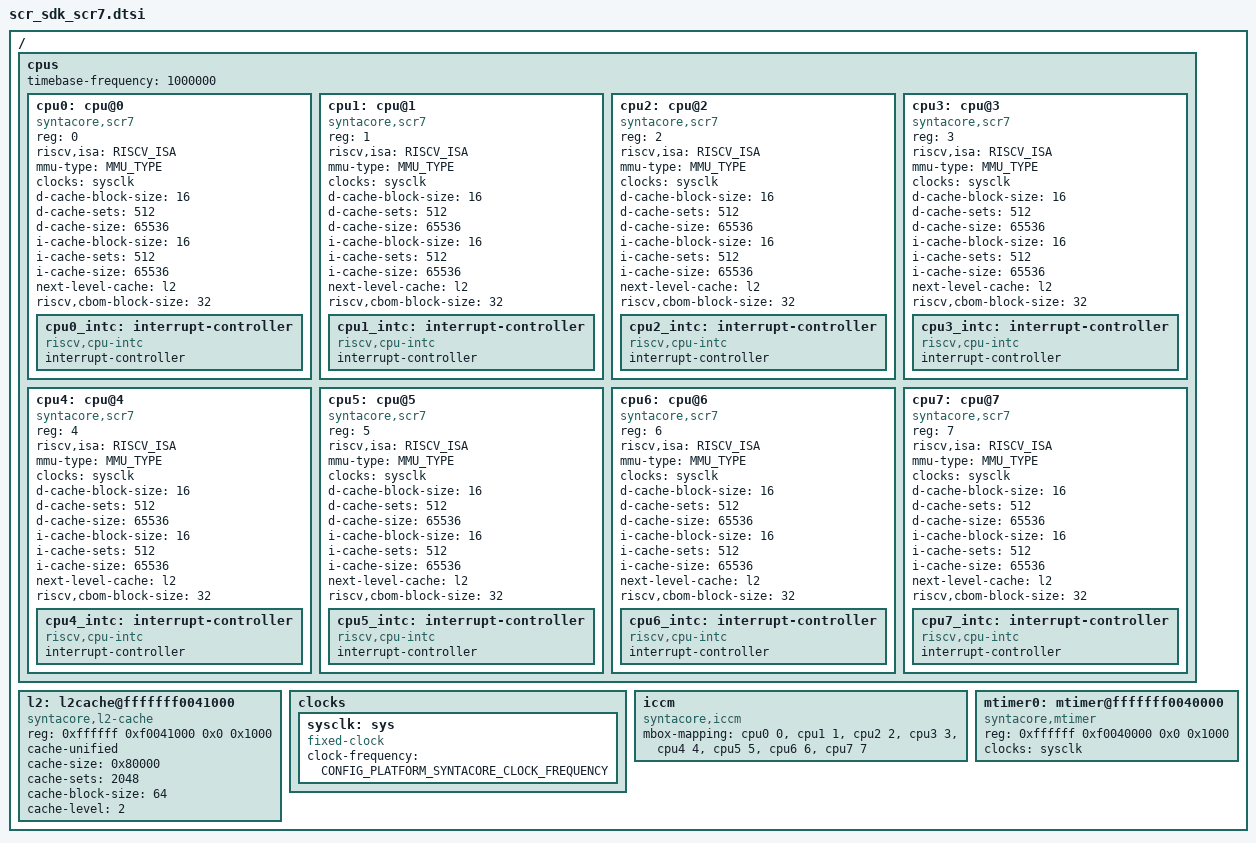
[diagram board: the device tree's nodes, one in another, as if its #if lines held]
/*
 * Copyright (C) 2022, Syntacore Ltd.
 *
 * Redistribution and use in source and binary forms, with or without
 * modification, are permitted provided that the following conditions are met:
 *     1. Redistributions of source code must retain the above copyright notice,
 *        this list of conditions and the following disclaimer.
 *     2. Redistributions in binary form must reproduce the above copyright
 *        notice, this list of conditions and the following disclaimer in the
 *        documentation and/or other materials provided with the distribution.
 *     3. Neither the name of the copyright holder nor the names of its
 *        contributors may be used to endorse or promote products derived from
 *        this software without specific prior written permission.
 *
 * THIS SOFTWARE IS PROVIDED BY THE COPYRIGHT HOLDERS AND CONTRIBUTORS "AS IS" AND
 * ANY EXPRESS OR IMPLIED WARRANTIES, INCLUDING, BUT NOT LIMITED TO, THE IMPLIED
 * WARRANTIES OF MERCHANTABILITY AND FITNESS FOR A PARTICULAR PURPOSE ARE
 * DISCLAIMED. IN NO EVENT SHALL THE COPYRIGHT HOLDER OR CONTRIBUTORS BE LIABLE
 * FOR ANY DIRECT, INDIRECT, INCIDENTAL, SPECIAL, EXEMPLARY, OR CONSEQUENTIAL
 * DAMAGES (INCLUDING, BUT NOT LIMITED TO, PROCUREMENT OF SUBSTITUTE GOODS OR
 * SERVICES; LOSS OF USE, DATA, OR PROFITS; OR BUSINESS INTERRUPTION) HOWEVER
 * CAUSED AND ON ANY THEORY OF LIABILITY, WHETHER IN CONTRACT, STRICT LIABILITY,
 * OR TORT (INCLUDING NEGLIGENCE OR OTHERWISE) ARISING IN ANY WAY OUT OF THE USE
 * OF THIS SOFTWARE, EVEN IF ADVISED OF THE POSSIBILITY OF SUCH DAMAGE.
 */

#define RISCV_ISA	"rv64imafdc_sscofpmf"
#define MMU_TYPE	"riscv,sv39"

/ {
	cpus {
		#address-cells = <1>;
		#size-cells = <0>;
		timebase-frequency = <1000000>;

		cpu0: cpu@0 {
			device_type = "cpu";
			reg = <0>;
			status = "okay";
			compatible = "syntacore,scr7","riscv";
			riscv,isa = RISCV_ISA;
			mmu-type = MMU_TYPE;
			clocks = <&sysclk>;
			d-cache-block-size = <16>;
			d-cache-sets = <512>;
			d-cache-size = <65536>;
			i-cache-block-size = <16>;
			i-cache-sets = <512>;
			i-cache-size = <65536>;
			next-level-cache = <&l2>;
			riscv,cbom-block-size = <32>;

			cpu0_intc: interrupt-controller {
				#address-cells = <0>;
				#interrupt-cells = <1>;
				interrupt-controller;
				compatible = "riscv,cpu-intc";
			};
		};

#if CONFIG_PLATFORM_SYNTACORE_NR_CPUS > 1
		cpu1: cpu@1 {
			device_type = "cpu";
			reg = <1>;
			status = "okay";
			compatible = "syntacore,scr7","riscv";
			riscv,isa = RISCV_ISA;
			mmu-type = MMU_TYPE;
			clocks = <&sysclk>;
			d-cache-block-size = <16>;
			d-cache-sets = <512>;
			d-cache-size = <65536>;
			i-cache-block-size = <16>;
			i-cache-sets = <512>;
			i-cache-size = <65536>;
			next-level-cache = <&l2>;
			riscv,cbom-block-size = <32>;

			cpu1_intc: interrupt-controller {
				#address-cells = <0>;
				#interrupt-cells = <1>;
				interrupt-controller;
				compatible = "riscv,cpu-intc";
			};
		};
#endif

#if CONFIG_PLATFORM_SYNTACORE_NR_CPUS > 2
		cpu2: cpu@2 {
			device_type = "cpu";
			reg = <2>;
			status = "okay";
			compatible = "syntacore,scr7","riscv";
			riscv,isa = RISCV_ISA;
			mmu-type = MMU_TYPE;
			clocks = <&sysclk>;
			d-cache-block-size = <16>;
			d-cache-sets = <512>;
			d-cache-size = <65536>;
			i-cache-block-size = <16>;
			i-cache-sets = <512>;
			i-cache-size = <65536>;
			next-level-cache = <&l2>;
			riscv,cbom-block-size = <32>;

			cpu2_intc: interrupt-controller {
				#address-cells = <0>;
				#interrupt-cells = <1>;
				interrupt-controller;
				compatible = "riscv,cpu-intc";
			};
		};
#endif

#if CONFIG_PLATFORM_SYNTACORE_NR_CPUS > 3
		cpu3: cpu@3 {
			device_type = "cpu";
			reg = <3>;
			status = "okay";
			compatible = "syntacore,scr7","riscv";
			riscv,isa = RISCV_ISA;
			mmu-type = MMU_TYPE;
			clocks = <&sysclk>;
			d-cache-block-size = <16>;
			d-cache-sets = <512>;
			d-cache-size = <65536>;
			i-cache-block-size = <16>;
			i-cache-sets = <512>;
			i-cache-size = <65536>;
			next-level-cache = <&l2>;
			riscv,cbom-block-size = <32>;

			cpu3_intc: interrupt-controller {
				#address-cells = <0>;
				#interrupt-cells = <1>;
				interrupt-controller;
				compatible = "riscv,cpu-intc";
			};
		};
#endif

#if CONFIG_PLATFORM_SYNTACORE_NR_CPUS > 4
		cpu4: cpu@4 {
			device_type = "cpu";
			reg = <4>;
			status = "okay";
			compatible = "syntacore,scr7","riscv";
			riscv,isa = RISCV_ISA;
			mmu-type = MMU_TYPE;
			clocks = <&sysclk>;
			d-cache-block-size = <16>;
			d-cache-sets = <512>;
			d-cache-size = <65536>;
			i-cache-block-size = <16>;
			i-cache-sets = <512>;
			i-cache-size = <65536>;
			next-level-cache = <&l2>;
			riscv,cbom-block-size = <32>;

			cpu4_intc: interrupt-controller {
				#address-cells = <0>;
				#interrupt-cells = <1>;
				interrupt-controller;
				compatible = "riscv,cpu-intc";
			};
		};
#endif

#if CONFIG_PLATFORM_SYNTACORE_NR_CPUS > 5
		cpu5: cpu@5 {
			device_type = "cpu";
			reg = <5>;
			status = "okay";
			compatible = "syntacore,scr7","riscv";
			riscv,isa = RISCV_ISA;
			mmu-type = MMU_TYPE;
			clocks = <&sysclk>;
			d-cache-block-size = <16>;
			d-cache-sets = <512>;
			d-cache-size = <65536>;
			i-cache-block-size = <16>;
			i-cache-sets = <512>;
			i-cache-size = <65536>;
			next-level-cache = <&l2>;
			riscv,cbom-block-size = <32>;

			cpu5_intc: interrupt-controller {
				#address-cells = <0>;
				#interrupt-cells = <1>;
				interrupt-controller;
				compatible = "riscv,cpu-intc";
			};
		};
#endif

#if CONFIG_PLATFORM_SYNTACORE_NR_CPUS > 6
		cpu6: cpu@6 {
			device_type = "cpu";
			reg = <6>;
			status = "okay";
			compatible = "syntacore,scr7","riscv";
			riscv,isa = RISCV_ISA;
			mmu-type = MMU_TYPE;
			clocks = <&sysclk>;
			d-cache-block-size = <16>;
			d-cache-sets = <512>;
			d-cache-size = <65536>;
			i-cache-block-size = <16>;
			i-cache-sets = <512>;
			i-cache-size = <65536>;
			next-level-cache = <&l2>;
			riscv,cbom-block-size = <32>;

			cpu6_intc: interrupt-controller {
				#address-cells = <0>;
				#interrupt-cells = <1>;
				interrupt-controller;
				compatible = "riscv,cpu-intc";
			};
		};
#endif

#if CONFIG_PLATFORM_SYNTACORE_NR_CPUS > 7
		cpu7: cpu@7 {
			device_type = "cpu";
			reg = <7>;
			status = "okay";
			compatible = "syntacore,scr7","riscv";
			riscv,isa = RISCV_ISA;
			mmu-type = MMU_TYPE;
			clocks = <&sysclk>;
			d-cache-block-size = <16>;
			d-cache-sets = <512>;
			d-cache-size = <65536>;
			i-cache-block-size = <16>;
			i-cache-sets = <512>;
			i-cache-size = <65536>;
			next-level-cache = <&l2>;
			riscv,cbom-block-size = <32>;

			cpu7_intc: interrupt-controller {
				#address-cells = <0>;
				#interrupt-cells = <1>;
				interrupt-controller;
				compatible = "riscv,cpu-intc";
			};
		};
#endif
	};

	l2: l2cache@fffffff0041000 {
		compatible = "syntacore,l2-cache", "cache";
		reg = <0xffffff 0xf0041000 0x0 0x1000>;
		cache-unified;
		cache-size = <0x80000>; // 512 KB
		cache-sets = <2048>;
		cache-block-size = <64>;
		cache-level = <2>;
	};

	clocks {
		sysclk: sys {
			compatible = "fixed-clock";
			#clock-cells = <0>;
			clock-frequency = <CONFIG_PLATFORM_SYNTACORE_CLOCK_FREQUENCY>;
		};
	};

	iccm {
		compatible = "syntacore,iccm";
		mbox-mapping = <
			&cpu0 0
#if CONFIG_PLATFORM_SYNTACORE_NR_CPUS > 1
			&cpu1 1
#endif
#if CONFIG_PLATFORM_SYNTACORE_NR_CPUS > 2
			&cpu2 2
#endif
#if CONFIG_PLATFORM_SYNTACORE_NR_CPUS > 3
			&cpu3 3
#endif
#if CONFIG_PLATFORM_SYNTACORE_NR_CPUS > 4
			&cpu4 4
#endif
#if CONFIG_PLATFORM_SYNTACORE_NR_CPUS > 5
			&cpu5 5
#endif
#if CONFIG_PLATFORM_SYNTACORE_NR_CPUS > 6
			&cpu6 6
#endif
#if CONFIG_PLATFORM_SYNTACORE_NR_CPUS > 7
			&cpu7 7
#endif
		>;
	};

	mtimer0: mtimer@fffffff0040000 {
		compatible = "syntacore,mtimer";
		reg = <0xffffff 0xf0040000 0x0 0x1000>;
		clocks = <&sysclk>;
	};
};
